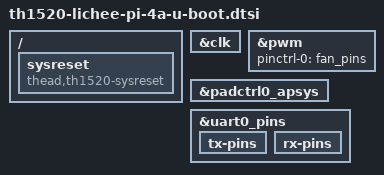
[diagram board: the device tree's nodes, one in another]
// SPDX-License-Identifier: GPL-2.0
/*
 * Copyright (C) 2025 Yao Zi <ziyao@disroot.org>
 */

#include "th1520-lichee-module-4a-u-boot.dtsi"
#include "thead-th1520-binman.dtsi"

/ {
	sysreset {
		compatible = "thead,th1520-sysreset";
	};
};

&clk {
	bootph-some-ram;
};

&pwm {
	pinctrl-names = "default";
	pinctrl-0 = <&fan_pins>;
	status = "okay";
};

&padctrl0_apsys {
	bootph-some-ram;
};

&uart0_pins {
	bootph-some-ram;

	tx-pins {
		bootph-some-ram;
	};

	rx-pins {
		bootph-some-ram;
	};
};
